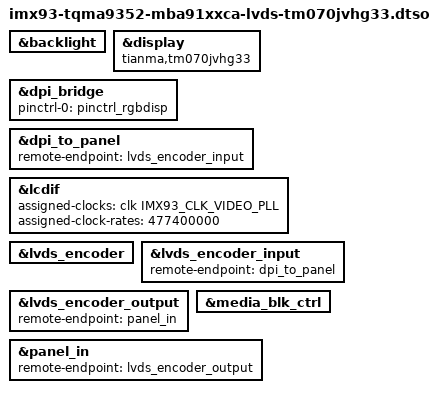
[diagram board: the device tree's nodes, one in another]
// SPDX-License-Identifier: (GPL-2.0-or-later OR MIT)
/*
 * Copyright (c) 2023-2026 TQ-Systems GmbH <linux@ew.tq-group.com>,
 * D-82229 Seefeld, Germany.
 * Author: Alexander Stein
 */

#include <dt-bindings/clock/imx93-clock.h>

/dts-v1/;
/plugin/;

&backlight {
	status = "okay";
};

&display {
	compatible = "tianma,tm070jvhg33";
	status = "okay";
};

&dpi_bridge {
	pinctrl-names = "default";
	pinctrl-0 = <&pinctrl_rgbdisp>;
	status = "okay";
};

&dpi_to_panel {
	remote-endpoint = <&lvds_encoder_input>;
};

&lcdif {
	assigned-clocks = <&clk IMX93_CLK_VIDEO_PLL>;
	assigned-clock-rates = <477400000>;
	status = "okay";
};

&lvds_encoder {
	status = "okay";
};

&lvds_encoder_input {
	remote-endpoint = <&dpi_to_panel>;
};

&lvds_encoder_output {
	remote-endpoint = <&panel_in>;
};

&media_blk_ctrl {
	status = "okay";
};

&panel_in {
	remote-endpoint = <&lvds_encoder_output>;
};
